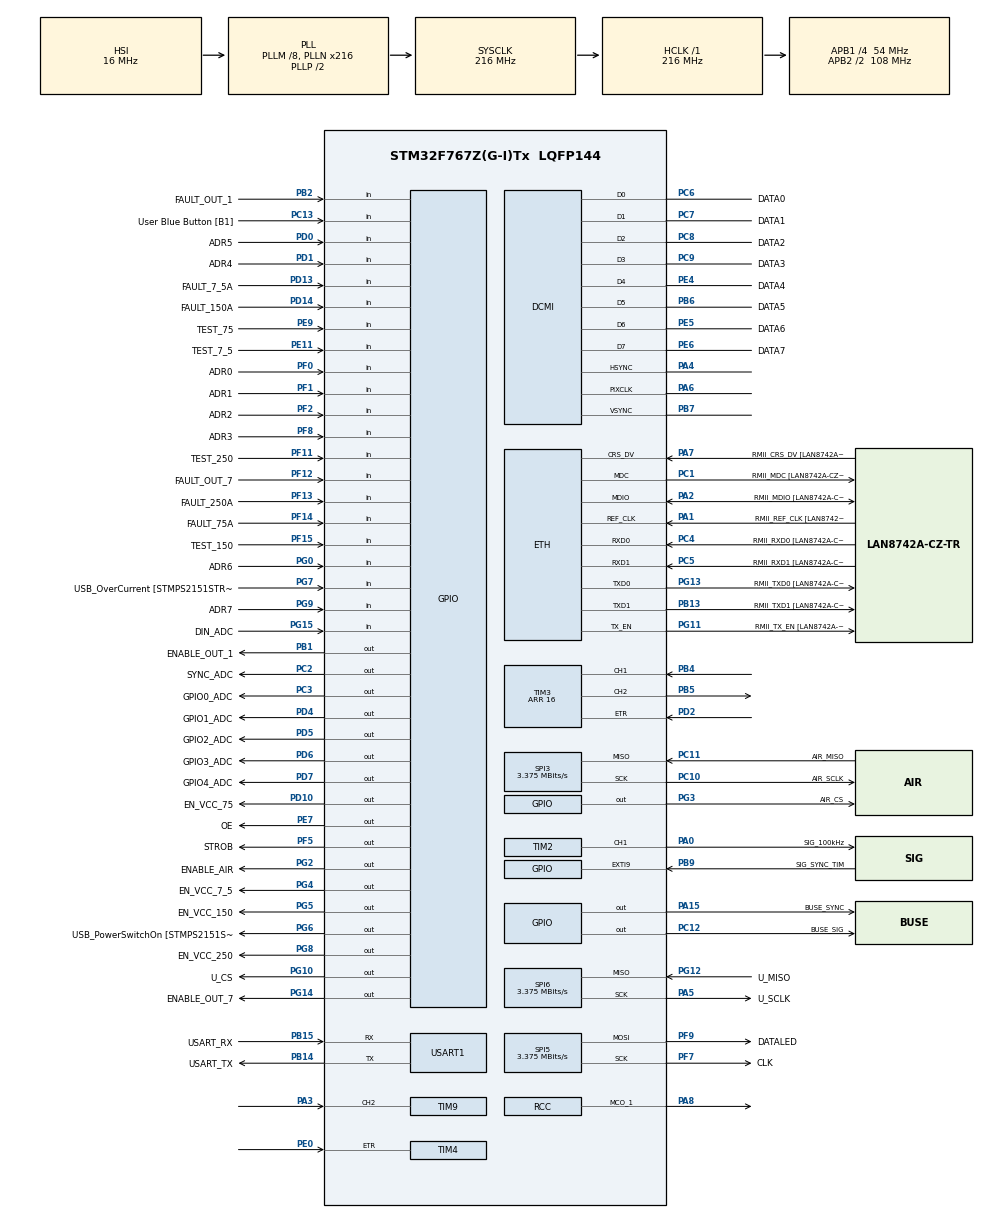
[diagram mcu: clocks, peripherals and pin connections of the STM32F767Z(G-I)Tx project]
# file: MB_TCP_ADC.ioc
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CORTEX_M7.ART_ACCLERATOR_ENABLE=1
CORTEX_M7.CPU_DCache=Disabled
CORTEX_M7.CPU_ICache=Enabled
CORTEX_M7.Enable-Cortex_Memory_Protection_Unit_Region0_Settings=__NULL
CORTEX_M7.MPU_Control=__NULL
CORTEX_M7.PREFETCH_ENABLE=1
Dma.DCMI.1.Direction=DMA_PERIPH_TO_MEMORY
Dma.DCMI.1.FIFOMode=DMA_FIFOMODE_DISABLE
Dma.DCMI.1.Instance=DMA2_Stream1
Dma.DCMI.1.MemDataAlignment=DMA_MDATAALIGN_WORD
Dma.DCMI.1.MemInc=DMA_MINC_ENABLE
Dma.DCMI.1.Mode=DMA_CIRCULAR
Dma.DCMI.1.PeriphDataAlignment=DMA_PDATAALIGN_WORD
Dma.DCMI.1.PeriphInc=DMA_PINC_DISABLE
Dma.DCMI.1.Priority=DMA_PRIORITY_LOW
Dma.Request0=SPI3_RX
Dma.Request1=DCMI
Dma.Request2=SPI6_RX
Dma.Request3=SPI5_TX
Dma.Request4=USART1_RX
Dma.Request5=USART1_TX
Dma.SPI3_RX.0.Direction=DMA_PERIPH_TO_MEMORY
Dma.SPI3_RX.0.FIFOMode=DMA_FIFOMODE_DISABLE
Dma.SPI3_RX.0.Instance=DMA1_Stream0
Dma.SPI3_RX.0.MemDataAlignment=DMA_MDATAALIGN_BYTE
Dma.SPI3_RX.0.MemInc=DMA_MINC_ENABLE
Dma.SPI3_RX.0.Mode=DMA_NORMAL
Dma.SPI3_RX.0.PeriphDataAlignment=DMA_PDATAALIGN_BYTE
Dma.SPI3_RX.0.PeriphInc=DMA_PINC_DISABLE
Dma.SPI3_RX.0.Priority=DMA_PRIORITY_LOW
Dma.SPI5_TX.3.Direction=DMA_MEMORY_TO_PERIPH
Dma.SPI5_TX.3.FIFOMode=DMA_FIFOMODE_DISABLE
Dma.SPI5_TX.3.Instance=DMA2_Stream4
Dma.SPI5_TX.3.MemDataAlignment=DMA_MDATAALIGN_BYTE
Dma.SPI5_TX.3.MemInc=DMA_MINC_ENABLE
Dma.SPI5_TX.3.Mode=DMA_NORMAL
Dma.SPI5_TX.3.PeriphDataAlignment=DMA_PDATAALIGN_BYTE
Dma.SPI5_TX.3.PeriphInc=DMA_PINC_DISABLE
Dma.SPI5_TX.3.Priority=DMA_PRIORITY_VERY_HIGH
Dma.SPI6_RX.2.Direction=DMA_PERIPH_TO_MEMORY
Dma.SPI6_RX.2.FIFOMode=DMA_FIFOMODE_DISABLE
Dma.SPI6_RX.2.Instance=DMA2_Stream6
Dma.SPI6_RX.2.MemDataAlignment=DMA_MDATAALIGN_BYTE
Dma.SPI6_RX.2.MemInc=DMA_MINC_ENABLE
Dma.SPI6_RX.2.Mode=DMA_NORMAL
Dma.SPI6_RX.2.PeriphDataAlignment=DMA_PDATAALIGN_BYTE
Dma.SPI6_RX.2.PeriphInc=DMA_PINC_DISABLE
Dma.SPI6_RX.2.Priority=DMA_PRIORITY_LOW
Dma.USART1_RX.4.Direction=DMA_PERIPH_TO_MEMORY
Dma.USART1_RX.4.FIFOMode=DMA_FIFOMODE_DISABLE
Dma.USART1_RX.4.Instance=DMA2_Stream2
Dma.USART1_RX.4.MemDataAlignment=DMA_MDATAALIGN_BYTE
Dma.USART1_RX.4.MemInc=DMA_MINC_ENABLE
Dma.USART1_RX.4.Mode=DMA_NORMAL
Dma.USART1_RX.4.PeriphDataAlignment=DMA_PDATAALIGN_BYTE
Dma.USART1_RX.4.PeriphInc=DMA_PINC_DISABLE
Dma.USART1_RX.4.Priority=DMA_PRIORITY_MEDIUM
Dma.USART1_TX.5.Direction=DMA_MEMORY_TO_PERIPH
Dma.USART1_TX.5.FIFOMode=DMA_FIFOMODE_DISABLE
Dma.USART1_TX.5.Instance=DMA2_Stream7
Dma.USART1_TX.5.MemDataAlignment=DMA_MDATAALIGN_BYTE
Dma.USART1_TX.5.MemInc=DMA_MINC_ENABLE
Dma.USART1_TX.5.Mode=DMA_NORMAL
Dma.USART1_TX.5.PeriphDataAlignment=DMA_PDATAALIGN_BYTE
Dma.USART1_TX.5.PeriphInc=DMA_PINC_DISABLE
Dma.USART1_TX.5.Priority=DMA_PRIORITY_MEDIUM
ETH.AutoNegotiation=ETH_AUTONEGOTIATION_ENABLE
ETH.MACAddr=00\:80\:E2\:20\:00\:00
ETH.MediaInterface=ETH_MEDIA_INTERFACE_RMII
ETH.PhyAddress=0
FREERTOS.INCLUDE_vTaskDelayUntil=1
FREERTOS.Tasks01=defaultTask,0,128,StartDefaultTask,Default,NULL,Dynamic,NULL,NULL
FREERTOS.configTOTAL_HEAP_SIZE=65536
LWIP.CHECKSUM_BY_HARDWARE=1
LWIP.GATEWAY_ADDRESS=192.168.109.008
LWIP.IP_ADDRESS=192.168.109.150
LWIP.LWIP_DHCP=0
LWIP.MEMP_NUM_RAW_PCB=8
LWIP.MEMP_NUM_UDP_PCB=1
LWIP.NETMASK_ADDRESS=255.255.255.000
LWIP.Version=v2.0.0_Cube
Mcu.Family=STM32F7
Mcu.Name=STM32F767Z(G-I)Tx
Mcu.Package=LQFP144
NVIC.DMA1_Stream0_IRQn=true\:5\:0\:false\:false\:true\:true\:true
NVIC.DMA2_Stream1_IRQn=true\:5\:0\:false\:false\:true\:true\:true
NVIC.DMA2_Stream2_IRQn=true\:5\:0\:false\:false\:true\:true\:true
NVIC.DMA2_Stream4_IRQn=true\:5\:0\:false\:false\:true\:true\:true
NVIC.DMA2_Stream6_IRQn=true\:5\:0\:false\:false\:true\:true\:true
NVIC.DMA2_Stream7_IRQn=true\:5\:0\:false\:false\:true\:true\:true
NVIC.ETH_IRQn=true\:5\:0\:true\:false\:true\:true\:true
NVIC.EXTI9_5_IRQn=true\:5\:0\:false\:false\:true\:true\:true
NVIC.PriorityGroup=NVIC_PRIORITYGROUP_4
NVIC.TIM1_BRK_TIM9_IRQn=true\:5\:0\:false\:false\:true\:true\:true
NVIC.TIM6_DAC_IRQn=true\:5\:0\:false\:false\:true\:true\:true
NVIC.USART1_IRQn=true\:5\:0\:false\:false\:true\:true\:true
PA0/WKUP.GPIO_Label=SIG_100kHz
PA0/WKUP.Signal=S_TIM2_CH1_ETR
PA1.GPIO_Label=RMII_REF_CLK [LAN8742A-CZ-TR_REFCLK0]
PA1.Mode=RMII
PA1.Signal=ETH_REF_CLK
PA13.GPIO_Label=TMS
PA13.Mode=Trace_Asynchronous_SW
PA13.Signal=SYS_JTMS-SWDIO
PA14.GPIO_Label=TCK
PA14.Mode=Trace_Asynchronous_SW
PA14.Signal=SYS_JTCK-SWCLK
PA15.GPIO_Label=BUSE_SYNC
PA15.PinState=GPIO_PIN_SET
PA15.Signal=GPIO_Output
PA2.GPIO_Label=RMII_MDIO [LAN8742A-CZ-TR_MDIO]
PA2.Mode=RMII
PA2.Signal=ETH_MDIO
PA3.Signal=S_TIM9_CH2
PA4.Mode=Slave_8_bits_External_Synchro
PA4.Signal=DCMI_HSYNC
PA5.GPIO_Label=U_SCLK
PA5.Mode=RX_Only_Simplex_Unidirect_Master
PA5.Signal=SPI6_SCK
PA6.Mode=Slave_8_bits_External_Synchro
PA6.Signal=DCMI_PIXCLK
PA7.GPIO_Label=RMII_CRS_DV [LAN8742A-CZ-TR_CRS_DV]
PA7.Mode=RMII
PA7.Signal=ETH_CRS_DV
PA8.Mode=Clock-out-1
PA8.Signal=RCC_MCO_1
PB1.GPIO_Label=ENABLE_OUT_1
PB1.PinState=GPIO_PIN_RESET
PB1.Signal=GPIO_Output
PB13.GPIO_Label=RMII_TXD1 [LAN8742A-CZ-TR_TXD1]
PB13.Mode=RMII
PB13.Signal=ETH_TXD1
PB14.GPIO_Label=USART_TX
PB14.Mode=Asynchronous
PB14.Signal=USART1_TX
PB15.GPIO_Label=USART_RX
PB15.Mode=Asynchronous
PB15.Signal=USART1_RX
PB2.GPIO_Label=FAULT_OUT_1
PB2.Signal=GPIO_Input
PB3.Mode=Trace_Asynchronous_SW
PB3.Signal=SYS_JTDO-SWO
PB4.Signal=S_TIM3_CH1
PB5.Signal=S_TIM3_CH2
PB6.GPIO_Label=DATA5
PB6.Mode=Slave_8_bits_External_Synchro
PB6.Signal=DCMI_D5
PB7.Mode=Slave_8_bits_External_Synchro
PB7.Signal=DCMI_VSYNC
PB9.GPIO_Label=SIG_SYNC_TIM
PB9.Signal=GPXTI9
PC1.GPIO_Label=RMII_MDC [LAN8742A-CZ-TR_MDC]
PC1.Mode=RMII
PC1.Signal=ETH_MDC
PC10.GPIO_Label=AIR_SCLK
PC10.Mode=RX_Only_Simplex_Unidirect_Master
PC10.Signal=SPI3_SCK
PC11.GPIO_Label=AIR_MISO
PC11.Mode=RX_Only_Simplex_Unidirect_Master
PC11.Signal=SPI3_MISO
PC12.GPIO_Label=BUSE_SIG
PC12.Signal=GPIO_Output
PC13.GPIO_Label=User Blue Button [B1]
PC13.Signal=GPIO_Input
PC14/OSC32_IN.Signal=RCC_OSC32_IN
PC15/OSC32_OUT.Signal=RCC_OSC32_OUT
PC2.GPIO_Label=SYNC_ADC
PC2.Signal=GPIO_Output
PC3.GPIO_Label=GPIO0_ADC
PC3.Signal=GPIO_Output
PC4.GPIO_Label=RMII_RXD0 [LAN8742A-CZ-TR_RXD0]
PC4.Mode=RMII
PC4.Signal=ETH_RXD0
PC5.GPIO_Label=RMII_RXD1 [LAN8742A-CZ-TR_RXD1]
PC5.Mode=RMII
PC5.Signal=ETH_RXD1
PC6.GPIO_Label=DATA0
PC6.Mode=Slave_8_bits_External_Synchro
PC6.Signal=DCMI_D0
PC7.GPIO_Label=DATA1
PC7.Mode=Slave_8_bits_External_Synchro
PC7.Signal=DCMI_D1
PC8.GPIO_Label=DATA2
PC8.Mode=Slave_8_bits_External_Synchro
PC8.Signal=DCMI_D2
PC9.GPIO_Label=DATA3
PC9.Mode=Slave_8_bits_External_Synchro
PC9.Signal=DCMI_D3
PD0.GPIO_Label=ADR5
PD0.GPIO_PuPd=GPIO_PULLDOWN
PD0.Signal=GPIO_Input
PD1.GPIO_Label=ADR4
PD1.GPIO_PuPd=GPIO_PULLDOWN
PD1.Signal=GPIO_Input
PD10.GPIO_Label=EN_VCC_75
PD10.Signal=GPIO_Output
PD13.GPIO_Label=FAULT_7_5A
PD13.Signal=GPIO_Input
PD14.GPIO_Label=FAULT_150A
PD14.Signal=GPIO_Input
PD2.Signal=S_TIM3_ETR
PD4.GPIO_Label=GPIO1_ADC
PD4.Signal=GPIO_Output
PD5.GPIO_Label=GPIO2_ADC
PD5.Signal=GPIO_Output
PD6.GPIO_Label=GPIO3_ADC
PD6.Signal=GPIO_Output
PD7.GPIO_Label=GPIO4_ADC
PD7.Signal=GPIO_Output
PD8.GPIO_Label=STLK_RX [STM32F103CBT6_PA3]
PD8.Signal=USART3_TX
PD9.GPIO_Label=STLK_TX [STM32F103CBT6_PA2]
PD9.Signal=USART3_RX
PE0.Signal=S_TIM4_ETR
PE11.GPIO_Label=TEST_7_5
PE11.Signal=GPIO_Input
PE4.GPIO_Label=DATA4
PE4.Mode=Slave_8_bits_External_Synchro
PE4.Signal=DCMI_D4
PE5.GPIO_Label=DATA6
PE5.Mode=Slave_8_bits_External_Synchro
PE5.Signal=DCMI_D6
PE6.GPIO_Label=DATA7
PE6.Mode=Slave_8_bits_External_Synchro
PE6.Signal=DCMI_D7
PE7.GPIO_Label=OE
PE7.Signal=GPIO_Output
PE9.GPIO_Label=TEST_75
PE9.Signal=GPIO_Input
PF0.GPIO_Label=ADR0
PF0.GPIO_PuPd=GPIO_PULLDOWN
PF0.Signal=GPIO_Input
PF1.GPIO_Label=ADR1
PF1.GPIO_PuPd=GPIO_PULLDOWN
PF1.Signal=GPIO_Input
PF11.GPIO_Label=TEST_250
PF11.Signal=GPIO_Input
PF12.GPIO_Label=FAULT_OUT_7
PF12.Signal=GPIO_Input
PF13.GPIO_Label=FAULT_250A
PF13.Signal=GPIO_Input
PF14.GPIO_Label=FAULT_75A
PF14.Signal=GPIO_Input
PF15.GPIO_Label=TEST_150
PF15.Signal=GPIO_Input
PF2.GPIO_Label=ADR2
PF2.GPIO_PuPd=GPIO_PULLDOWN
PF2.Signal=GPIO_Input
PF5.GPIO_Label=STROB
PF5.Signal=GPIO_Output
PF7.GPIO_Label=CLK
PF7.Mode=TX_Only_Simplex_Unidirect_Master
PF7.Signal=SPI5_SCK
PF8.GPIO_Label=ADR3
PF8.Signal=GPIO_Input
PF9.GPIO_Label=DATALED
PF9.Mode=TX_Only_Simplex_Unidirect_Master
PF9.Signal=SPI5_MOSI
PG0.GPIO_Label=ADR6
PG0.GPIO_PuPd=GPIO_PULLUP
PG0.Signal=GPIO_Input
PG10.GPIO_Label=U_CS
PG10.Signal=GPIO_Output
PG11.GPIO_Label=RMII_TX_EN [LAN8742A-CZ-TR_TXEN]
PG11.Mode=RMII
PG11.Signal=ETH_TX_EN
PG12.GPIO_Label=U_MISO
PG12.Mode=RX_Only_Simplex_Unidirect_Master
PG12.Signal=SPI6_MISO
PG13.GPIO_Label=RMII_TXD0 [LAN8742A-CZ-TR_TXD0]
PG13.Mode=RMII
PG13.Signal=ETH_TXD0
PG14.GPIO_Label=ENABLE_OUT_7
PG14.PinState=GPIO_PIN_SET
PG14.Signal=GPIO_Output
PG15.GPIO_Label=DIN_ADC
PG15.Signal=GPIO_Input
PG2.GPIO_Label=ENABLE_AIR
PG2.Signal=GPIO_Output
PG3.GPIO_Label=AIR_CS
PG3.Signal=GPIO_Output
PG4.GPIO_Label=EN_VCC_7_5
PG4.Signal=GPIO_Output
PG5.GPIO_Label=EN_VCC_150
PG5.Signal=GPIO_Output
PG6.GPIO_Label=USB_PowerSwitchOn [STMPS2151STR_EN]
PG6.Signal=GPIO_Output
PG7.GPIO_Label=USB_OverCurrent [STMPS2151STR_FAULT]
PG7.Signal=GPIO_Input
PG8.GPIO_Label=EN_VCC_250
PG8.Signal=GPIO_Output
PG9.GPIO_Label=ADR7
PG9.GPIO_PuPd=GPIO_PULLUP
PG9.Signal=GPIO_Input
PH0/OSC_IN.GPIO_Label=MCO [STM32F103CBT6_PA8]
PH0/OSC_IN.Mode=HSE-External-Oscillator
PH0/OSC_IN.Signal=RCC_OSC_IN
PH1/OSC_OUT.Mode=HSE-External-Oscillator
PH1/OSC_OUT.Signal=RCC_OSC_OUT
ProjectManager.HeapSize=0x2000
ProjectManager.StackSize=0x4000
ProjectManager.TargetToolchain=MDK-ARM V5
RCC.48MHZClocksFreq_Value=24000000
RCC.AHBFreq_Value=216000000
RCC.APB1CLKDivider=RCC_HCLK_DIV4
RCC.APB1Freq_Value=54000000
RCC.APB1TimFreq_Value=108000000
RCC.APB2CLKDivider=RCC_HCLK_DIV2
RCC.APB2Freq_Value=108000000
RCC.APB2TimFreq_Value=216000000
RCC.CortexFreq_Value=216000000
RCC.HCLKFreq_Value=216000000
RCC.HSE_VALUE=8000000
RCC.HSI_VALUE=16000000
RCC.LSE_VALUE=32768
RCC.PLLM=8
RCC.PLLMUL=RCC_PLL_MUL9
RCC.PLLN=216
RCC.PRESCALERUSB=RCC_USBCLKSOURCE_PLL_DIV1_5
RCC.RCC_MCODiv1=RCC_MCODIV_2
RCC.SYSCLKFreq_VALUE=216000000
RCC.SYSCLKSource=RCC_SYSCLKSOURCE_PLLCLK
RCC.SYSCLKSourceVirtual=RCC_SYSCLKSOURCE_PLLCLK
RCC.USBFreq_Value=216000000
RCC.VCOOutputFreq_Value=432000000
SH.S_TIM2_CH1_ETR.0=TIM2_CH1,PWM Generation1 CH1
SH.S_TIM3_CH1.0=TIM3_CH1,TriggerSource_TI1FP1
SH.S_TIM3_CH2.0=TIM3_CH2,PWM Generation2 CH2
SH.S_TIM3_ETR.0=TIM3_ETR,ClockSourceETR_Mode2
SH.S_TIM4_ETR.0=TIM4_ETR,ClockSourceETR_Mode2
SH.S_TIM9_CH2.0=TIM9_CH2,TriggerSource_TI2FP2
SPI3.BaudRatePrescaler=SPI_BAUDRATEPRESCALER_16
SPI3.CLKPolarity=SPI_POLARITY_HIGH
SPI3.CalculateBaudRate=3.375 MBits/s
SPI3.DataSize=SPI_DATASIZE_8BIT
SPI3.Direction=SPI_DIRECTION_2LINES_RXONLY
SPI3.Mode=SPI_MODE_MASTER
SPI3.NSSPMode=SPI_NSS_PULSE_DISABLE
SPI3.VirtualType=VM_MASTER
SPI5.BaudRatePrescaler=SPI_BAUDRATEPRESCALER_32
SPI5.CalculateBaudRate=3.375 MBits/s
SPI5.DataSize=SPI_DATASIZE_8BIT
SPI5.Direction=SPI_DIRECTION_2LINES
SPI5.Mode=SPI_MODE_MASTER
SPI5.NSSPMode=SPI_NSS_PULSE_DISABLE
SPI5.VirtualType=VM_MASTER
SPI6.BaudRatePrescaler=SPI_BAUDRATEPRESCALER_32
SPI6.CLKPolarity=SPI_POLARITY_HIGH
SPI6.CalculateBaudRate=3.375 MBits/s
SPI6.DataSize=SPI_DATASIZE_8BIT
SPI6.Direction=SPI_DIRECTION_2LINES_RXONLY
SPI6.Mode=SPI_MODE_MASTER
SPI6.NSSPMode=SPI_NSS_PULSE_DISABLE
SPI6.VirtualType=VM_MASTER
TIM2.Channel-PWM\ Generation1\ CH1=TIM_CHANNEL_1
TIM2.Period=1080
TIM2.Pulse-PWM\ Generation1\ CH1=540
TIM2.TIM_MasterOutputTrigger=TIM_TRGO_UPDATE
TIM2.TIM_MasterSlaveMode=TIM_MASTERSLAVEMODE_ENABLE
TIM3.Channel-PWM\ Generation2\ CH2=TIM_CHANNEL_2
TIM3.OCMode_PWM-PWM\ Generation2\ CH2=TIM_OCMODE_PWM2
TIM3.Period=16
TIM3.Pulse-PWM\ Generation2\ CH2=1
TIM4.Period=0xFFFF
TIM4.Prescaler=0
TIM4.TIM_MasterOutputTrigger=TIM_TRGO_UPDATE
TIM4.TIM_MasterSlaveMode=TIM_MASTERSLAVEMODE_ENABLE
TIM5.Period=0xFFFFFFFF
TIM6.Period=50-1
TIM6.Prescaler=108
TIM9.Period=4-1
USART1.VirtualMode-Asynchronous=VM_ASYNC
VP_FREERTOS_VS_ENABLE.Mode=Enabled
VP_LWIP_VS_Enabled.Mode=Enabled
VP_TIM2_VS_ClockSourceINT.Mode=Internal
VP_TIM3_VS_ControllerModeTrigger.Mode=Trigger Mode
VP_TIM3_VS_OPM.Mode=OPM_bit
VP_TIM5_VS_ClockSourceITR.Mode=TriggerSource_ITR2
VP_TIM5_VS_ControllerModeClock.Mode=Clock Mode
VP_TIM6_VS_ClockSourceINT.Mode=Enable_Timer
VP_TIM9_VS_ControllerModeClock.Mode=Clock Mode
board=MB_TCP_ADC

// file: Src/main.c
/**
  ******************************************************************************
  * File Name          : main.c
  * Description        : Main program body
  ******************************************************************************
  * This notice applies to any and all portions of this file
  * that are not between comment pairs USER CODE BEGIN and
  * USER CODE END. Other portions of this file, whether
  * inserted by the user or by software development tools
  * are owned by their respective copyright owners.
  *
  * Copyright (c) 2017 STMicroelectronics International N.V.
  * All rights reserved.
  *
  * Redistribution and use in source and binary forms, with or without
  * modification, are permitted, provided that the following conditions are met:
  *
  * 1. Redistribution of source code must retain the above copyright notice,
  *    this list of conditions and the following disclaimer.
  * 2. Redistributions in binary form must reproduce the above copyright notice,
  *    this list of conditions and the following disclaimer in the documentation
  *    and/or other materials provided with the distribution.
  * 3. Neither the name of STMicroelectronics nor the names of other
  *    contributors to this software may be used to endorse or promote products
  *    derived from this software without specific written permission.
  * 4. This software, including modifications and/or derivative works of this
  *    software, must execute solely and exclusively on microcontroller or
  *    microprocessor devices manufactured by or for STMicroelectronics.
  * 5. Redistribution and use of this software other than as permitted under
  *    this license is void and will automatically terminate your rights under
  *    this license.
  *
  * THIS SOFTWARE IS PROVIDED BY STMICROELECTRONICS AND CONTRIBUTORS "AS IS"
  * AND ANY EXPRESS, IMPLIED OR STATUTORY WARRANTIES, INCLUDING, BUT NOT
  * LIMITED TO, THE IMPLIED WARRANTIES OF MERCHANTABILITY, FITNESS FOR A
  * PARTICULAR PURPOSE AND NON-INFRINGEMENT OF THIRD PARTY INTELLECTUAL PROPERTY
  * RIGHTS ARE DISCLAIMED TO THE FULLEST EXTENT PERMITTED BY LAW. IN NO EVENT
  * SHALL STMICROELECTRONICS OR CONTRIBUTORS BE LIABLE FOR ANY DIRECT, INDIRECT,
  * INCIDENTAL, SPECIAL, EXEMPLARY, OR CONSEQUENTIAL DAMAGES (INCLUDING, BUT NOT
  * LIMITED TO, PROCUREMENT OF SUBSTITUTE GOODS OR SERVICES; LOSS OF USE, DATA,
  * OR PROFITS; OR BUSINESS INTERRUPTION) HOWEVER CAUSED AND ON ANY THEORY OF
  * LIABILITY, WHETHER IN CONTRACT, STRICT LIABILITY, OR TORT (INCLUDING
  * NEGLIGENCE OR OTHERWISE) ARISING IN ANY WAY OUT OF THE USE OF THIS SOFTWARE,
  * EVEN IF ADVISED OF THE POSSIBILITY OF SUCH DAMAGE.
  *
  ******************************************************************************
  */
#include "main.h"
#include "stm32f7xx_hal.h"
#include "cmsis_os.h"
#include "lwip.h"

/* USER CODE BEGIN Includes */
#include "mbinit.h"
#include "udp_send.h"
#include "adc_dcmi.h"
#include "cfg_info.h"
#include "discret_out.h"
#include "jumpers.h"
#include "mbmasterpyro.h"
/* USER CODE END Includes */

DCMI_HandleTypeDef hdcmi;
DMA_HandleTypeDef hdma_dcmi;

SPI_HandleTypeDef hspi3;
SPI_HandleTypeDef hspi5;
SPI_HandleTypeDef hspi6;
DMA_HandleTypeDef hdma_spi3_rx;
DMA_HandleTypeDef hdma_spi5_tx;
DMA_HandleTypeDef hdma_spi6_rx;

TIM_HandleTypeDef htim2;
TIM_HandleTypeDef htim3;
TIM_HandleTypeDef htim4;
TIM_HandleTypeDef htim5;
TIM_HandleTypeDef htim6;
TIM_HandleTypeDef htim9;

UART_HandleTypeDef huart1;
DMA_HandleTypeDef hdma_usart1_rx;
DMA_HandleTypeDef hdma_usart1_tx;

osThreadId defaultTaskHandle;

/* USER CODE BEGIN PV */
/* Private variables ---------------------------------------------------------*/

/* USER CODE END PV */

void SystemClock_Config(void);
static void MX_GPIO_Init(void);
static void MX_DMA_Init(void);
static void MX_DCMI_Init(void);
static void MX_TIM2_Init(void);
static void MX_TIM3_Init(void);
static void MX_TIM4_Init(void);
static void MX_TIM5_Init(void);
static void MX_USART1_UART_Init(void);
static void MX_SPI3_Init(void);
static void MX_SPI6_Init(void);
static void MX_TIM9_Init(void);
static void MX_SPI5_Init(void);
static void MX_TIM6_Init(void);
void StartDefaultTask(void const * argument);

void HAL_TIM_MspPostInit(TIM_HandleTypeDef *htim);

/* USER CODE BEGIN PFP */
/* Private function prototypes -----------------------------------------------*/

/* USER CODE END PFP */

/* USER CODE BEGIN 0 */
#include <stdio.h>

int fputc(int c, FILE *stream)
{
   return(ITM_SendChar(c));
}
/* USER CODE END 0 */

int main(void)
{

  /* Enable I-Cache-------------------------------------------------------------*/
  SCB_EnableICache();

  /* MCU Configuration----------------------------------------------------------*/

  /* Reset of all peripherals, Initializes the Flash interface and the Systick. */
  HAL_Init();

  /* Configure the system clock */
  SystemClock_Config();

  /* Initialize all configured peripherals */
  MX_GPIO_Init();
  MX_DMA_Init();
  MX_DCMI_Init();
  MX_TIM2_Init();
  MX_TIM3_Init();
  MX_TIM4_Init();
  MX_TIM5_Init();
  MX_USART1_UART_Init();
  MX_SPI3_Init();
  MX_SPI6_Init();
  MX_TIM9_Init();
  MX_SPI5_Init();
  MX_TIM6_Init();

  /* USER CODE BEGIN 2 */
	ConfigInfoRead();
	Jumpers_ReadSettings();
	DiscretOutputs_Init();
	DCMI_ADC_Init();
	ADC_DataConverter_Init();

  /* USER CODE END 2 */

  /* Create the thread(s) */
  /* definition and creation of defaultTask */
  osThreadDef(defaultTask, StartDefaultTask, osPriorityNormal, 0, 128);
  defaultTaskHandle = osThreadCreate(osThread(defaultTask), NULL);

  /* USER CODE BEGIN RTOS_QUEUES */
  /* add queues, ... */
		printf("Init");
		//HAL_TIM_PWM_Start(&htim2,TIM_CHANNEL_1);

  /* USER CODE END RTOS_QUEUES */

  /* Start scheduler */
  osKernelStart();

  /* We should never get here as control is now taken by the scheduler */

  /* Infinite loop */
  while (1)
  {

  }

}

/** System Clock Configuration
*/
void SystemClock_Config(void)
{

  RCC_OscInitTypeDef RCC_OscInitStruct;
  RCC_ClkInitTypeDef RCC_ClkInitStruct;
  RCC_PeriphCLKInitTypeDef PeriphClkInitStruct;

    /**Configure the main internal regulator output voltage
    */
  __HAL_RCC_PWR_CLK_ENABLE();

  __HAL_PWR_VOLTAGESCALING_CONFIG(PWR_REGULATOR_VOLTAGE_SCALE1);

    /**Initializes the CPU, AHB and APB busses clocks
    */
  RCC_OscInitStruct.OscillatorType = RCC_OSCILLATORTYPE_HSI;
  RCC_OscInitStruct.HSIState = RCC_HSI_ON;
  RCC_OscInitStruct.HSICalibrationValue = 16;
  RCC_OscInitStruct.PLL.PLLState = RCC_PLL_ON;
  RCC_OscInitStruct.PLL.PLLSource = RCC_PLLSOURCE_HSI;
  RCC_OscInitStruct.PLL.PLLM = 8;
  RCC_OscInitStruct.PLL.PLLN = 216;
  RCC_OscInitStruct.PLL.PLLP = RCC_PLLP_DIV2;
  RCC_OscInitStruct.PLL.PLLQ = 2;
  if (HAL_RCC_OscConfig(&RCC_OscInitStruct) != HAL_OK)
  {
    _Error_Handler(__FILE__, __LINE__);
  }

    /**Activate the Over-Drive mode
    */
  if (HAL_PWREx_EnableOverDrive() != HAL_OK)
  {
    _Error_Handler(__FILE__, __LINE__);
  }

    /**Initializes the CPU, AHB and APB busses clocks
    */
  RCC_ClkInitStruct.ClockType = RCC_CLOCKTYPE_HCLK|RCC_CLOCKTYPE_SYSCLK
                              |RCC_CLOCKTYPE_PCLK1|RCC_CLOCKTYPE_PCLK2;
  RCC_ClkInitStruct.SYSCLKSource = RCC_SYSCLKSOURCE_PLLCLK;
  RCC_ClkInitStruct.AHBCLKDivider = RCC_SYSCLK_DIV1;
  RCC_ClkInitStruct.APB1CLKDivider = RCC_HCLK_DIV4;
  RCC_ClkInitStruct.APB2CLKDivider = RCC_HCLK_DIV2;

  if (HAL_RCC_ClockConfig(&RCC_ClkInitStruct, FLASH_LATENCY_7) != HAL_OK)
  {
    _Error_Handler(__FILE__, __LINE__);
  }

  PeriphClkInitStruct.PeriphClockSelection = RCC_PERIPHCLK_USART1;
  PeriphClkInitStruct.Usart1ClockSelection = RCC_USART1CLKSOURCE_PCLK2;
  if (HAL_RCCEx_PeriphCLKConfig(&PeriphClkInitStruct) != HAL_OK)
  {
    _Error_Handler(__FILE__, __LINE__);
  }

  HAL_RCC_MCOConfig(RCC_MCO1, RCC_MCO1SOURCE_HSI, RCC_MCODIV_2);

    /**Configure the Systick interrupt time
    */
  HAL_SYSTICK_Config(HAL_RCC_GetHCLKFreq()/1000);

    /**Configure the Systick
    */
  HAL_SYSTICK_CLKSourceConfig(SYSTICK_CLKSOURCE_HCLK);

  /* SysTick_IRQn interrupt configuration */
  HAL_NVIC_SetPriority(SysTick_IRQn, 15, 0);
}

/* DCMI init function */
static void MX_DCMI_Init(void)
{

  hdcmi.Instance = DCMI;
  hdcmi.Init.SynchroMode = DCMI_SYNCHRO_HARDWARE;
  hdcmi.Init.PCKPolarity = DCMI_PCKPOLARITY_FALLING;
  hdcmi.Init.VSPolarity = DCMI_VSPOLARITY_LOW;
  hdcmi.Init.HSPolarity = DCMI_HSPOLARITY_LOW;
  hdcmi.Init.CaptureRate = DCMI_CR_ALL_FRAME;
  hdcmi.Init.ExtendedDataMode = DCMI_EXTEND_DATA_8B;
  hdcmi.Init.JPEGMode = DCMI_JPEG_DISABLE;
  hdcmi.Init.ByteSelectMode = DCMI_BSM_ALL;
  hdcmi.Init.ByteSelectStart = DCMI_OEBS_ODD;
  hdcmi.Init.LineSelectMode = DCMI_LSM_ALL;
  hdcmi.Init.LineSelectStart = DCMI_OELS_ODD;
  if (HAL_DCMI_Init(&hdcmi) != HAL_OK)
  {
    _Error_Handler(__FILE__, __LINE__);
  }

}

/* SPI3 init function */
static void MX_SPI3_Init(void)
{

  /* SPI3 parameter configuration*/
  hspi3.Instance = SPI3;
  hspi3.Init.Mode = SPI_MODE_MASTER;
  hspi3.Init.Direction = SPI_DIRECTION_2LINES_RXONLY;
  hspi3.Init.DataSize = SPI_DATASIZE_8BIT;
  hspi3.Init.CLKPolarity = SPI_POLARITY_HIGH;
  hspi3.Init.CLKPhase = SPI_PHASE_1EDGE;
  hspi3.Init.NSS = SPI_NSS_SOFT;
  hspi3.Init.BaudRatePrescaler = SPI_BAUDRATEPRESCALER_16;
  hspi3.Init.FirstBit = SPI_FIRSTBIT_MSB;
  hspi3.Init.TIMode = SPI_TIMODE_DISABLE;
  hspi3.Init.CRCCalculation = SPI_CRCCALCULATION_DISABLE;
  hspi3.Init.CRCPolynomial = 7;
  hspi3.Init.CRCLength = SPI_CRC_LENGTH_DATASIZE;
  hspi3.Init.NSSPMode = SPI_NSS_PULSE_DISABLE;
  if (HAL_SPI_Init(&hspi3) != HAL_OK)
  {
    _Error_Handler(__FILE__, __LINE__);
  }

}

/* SPI5 init function */
static void MX_SPI5_Init(void)
{

  /* SPI5 parameter configuration*/
  hspi5.Instance = SPI5;
  hspi5.Init.Mode = SPI_MODE_MASTER;
  hspi5.Init.Direction = SPI_DIRECTION_2LINES;
  hspi5.Init.DataSize = SPI_DATASIZE_8BIT;
  hspi5.Init.CLKPolarity = SPI_POLARITY_LOW;
  hspi5.Init.CLKPhase = SPI_PHASE_1EDGE;
  hspi5.Init.NSS = SPI_NSS_SOFT;
  hspi5.Init.BaudRatePrescaler = SPI_BAUDRATEPRESCALER_32;
  hspi5.Init.FirstBit = SPI_FIRSTBIT_MSB;
  hspi5.Init.TIMode = SPI_TIMODE_DISABLE;
  hspi5.Init.CRCCalculation = SPI_CRCCALCULATION_DISABLE;
  hspi5.Init.CRCPolynomial = 7;
  hspi5.Init.CRCLength = SPI_CRC_LENGTH_DATASIZE;
  hspi5.Init.NSSPMode = SPI_NSS_PULSE_DISABLE;
  if (HAL_SPI_Init(&hspi5) != HAL_OK)
  {
    _Error_Handler(__FILE__, __LINE__);
  }

}

/* SPI6 init function */
static void MX_SPI6_Init(void)
{

  /* SPI6 parameter configuration*/
  hspi6.Instance = SPI6;
  hspi6.Init.Mode = SPI_MODE_MASTER;
  hspi6.Init.Direction = SPI_DIRECTION_2LINES_RXONLY;
  hspi6.Init.DataSize = SPI_DATASIZE_8BIT;
  hspi6.Init.CLKPolarity = SPI_POLARITY_HIGH;
  hspi6.Init.CLKPhase = SPI_PHASE_1EDGE;
  hspi6.Init.NSS = SPI_NSS_SOFT;
  hspi6.Init.BaudRatePrescaler = SPI_BAUDRATEPRESCALER_32;
  hspi6.Init.FirstBit = SPI_FIRSTBIT_MSB;
  hspi6.Init.TIMode = SPI_TIMODE_DISABLE;
  hspi6.Init.CRCCalculation = SPI_CRCCALCULATION_DISABLE;
  hspi6.Init.CRCPolynomial = 7;
  hspi6.Init.CRCLength = SPI_CRC_LENGTH_DATASIZE;
  hspi6.Init.NSSPMode = SPI_NSS_PULSE_DISABLE;
  if (HAL_SPI_Init(&hspi6) != HAL_OK)
  {
    _Error_Handler(__FILE__, __LINE__);
  }

}

/* TIM2 init function */
static void MX_TIM2_Init(void)
{

  TIM_ClockConfigTypeDef sClockSourceConfig;
  TIM_MasterConfigTypeDef sMasterConfig;
  TIM_OC_InitTypeDef sConfigOC;

  htim2.Instance = TIM2;
  htim2.Init.Prescaler = 0;
  htim2.Init.CounterMode = TIM_COUNTERMODE_UP;
  htim2.Init.Period = 1080;
  htim2.Init.ClockDivision = TIM_CLOCKDIVISION_DIV1;
  htim2.Init.AutoReloadPreload = TIM_AUTORELOAD_PRELOAD_DISABLE;
  if (HAL_TIM_Base_Init(&htim2) != HAL_OK)
  {
    _Error_Handler(__FILE__, __LINE__);
  }

  sClockSourceConfig.ClockSource = TIM_CLOCKSOURCE_INTERNAL;
  if (HAL_TIM_ConfigClockSource(&htim2, &sClockSourceConfig) != HAL_OK)
  {
    _Error_Handler(__FILE__, __LINE__);
  }

  if (HAL_TIM_PWM_Init(&htim2) != HAL_OK)
  {
    _Error_Handler(__FILE__, __LINE__);
  }

  sMasterConfig.MasterOutputTrigger = TIM_TRGO_UPDATE;
  sMasterConfig.MasterSlaveMode = TIM_MASTERSLAVEMODE_ENABLE;
  if (HAL_TIMEx_MasterConfigSynchronization(&htim2, &sMasterConfig) != HAL_OK)
  {
    _Error_Handler(__FILE__, __LINE__);
  }

  sConfigOC.OCMode = TIM_OCMODE_PWM1;
  sConfigOC.Pulse = 540;
  sConfigOC.OCPolarity = TIM_OCPOLARITY_HIGH;
  sConfigOC.OCFastMode = TIM_OCFAST_DISABLE;
  if (HAL_TIM_PWM_ConfigChannel(&htim2, &sConfigOC, TIM_CHANNEL_1) != HAL_OK)
  {
    _Error_Handler(__FILE__, __LINE__);
  }

  HAL_TIM_MspPostInit(&htim2);

}

/* TIM3 init function */
static void MX_TIM3_Init(void)
{

  TIM_ClockConfigTypeDef sClockSourceConfig;
  TIM_SlaveConfigTypeDef sSlaveConfig;
  TIM_MasterConfigTypeDef sMasterConfig;
  TIM_OC_InitTypeDef sConfigOC;

  htim3.Instance = TIM3;
  htim3.Init.Prescaler = 0;
  htim3.Init.CounterMode = TIM_COUNTERMODE_UP;
  htim3.Init.Period = 16;
  htim3.Init.ClockDivision = TIM_CLOCKDIVISION_DIV1;
  htim3.Init.AutoReloadPreload = TIM_AUTORELOAD_PRELOAD_DISABLE;
  if (HAL_TIM_Base_Init(&htim3) != HAL_OK)
  {
    _Error_Handler(__FILE__, __LINE__);
  }

  sClockSourceConfig.ClockSource = TIM_CLOCKSOURCE_ETRMODE2;
  sClockSourceConfig.ClockPolarity = TIM_CLOCKPOLARITY_NONINVERTED;
  sClockSourceConfig.ClockPrescaler = TIM_CLOCKPRESCALER_DIV1;
  sClockSourceConfig.ClockFilter = 0;
  if (HAL_TIM_ConfigClockSource(&htim3, &sClockSourceConfig) != HAL_OK)
  {
    _Error_Handler(__FILE__, __LINE__);
  }

  if (HAL_TIM_PWM_Init(&htim3) != HAL_OK)
  {
    _Error_Handler(__FILE__, __LINE__);
  }

  if (HAL_TIM_OnePulse_Init(&htim3, TIM_OPMODE_SINGLE) != HAL_OK)
  {
    _Error_Handler(__FILE__, __LINE__);
  }

  sSlaveConfig.SlaveMode = TIM_SLAVEMODE_TRIGGER;
  sSlaveConfig.InputTrigger = TIM_TS_TI1FP1;
  sSlaveConfig.TriggerPolarity = TIM_TRIGGERPOLARITY_RISING;
  sSlaveConfig.TriggerFilter = 0;
  if (HAL_TIM_SlaveConfigSynchronization(&htim3, &sSlaveConfig) != HAL_OK)
  {
    _Error_Handler(__FILE__, __LINE__);
  }

  sMasterConfig.MasterOutputTrigger = TIM_TRGO_RESET;
  sMasterConfig.MasterSlaveMode = TIM_MASTERSLAVEMODE_DISABLE;
  if (HAL_TIMEx_MasterConfigSynchronization(&htim3, &sMasterConfig) != HAL_OK)
  {
    _Error_Handler(__FILE__, __LINE__);
  }

  sConfigOC.OCMode = TIM_OCMODE_PWM2;
  sConfigOC.Pulse = 1;
  sConfigOC.OCPolarity = TIM_OCPOLARITY_HIGH;
  sConfigOC.OCFastMode = TIM_OCFAST_DISABLE;
  if (HAL_TIM_PWM_ConfigChannel(&htim3, &sConfigOC, TIM_CHANNEL_2) != HAL_OK)
  {
    _Error_Handler(__FILE__, __LINE__);
  }

  HAL_TIM_MspPostInit(&htim3);

}

/* TIM4 init function */
static void MX_TIM4_Init(void)
{

  TIM_ClockConfigTypeDef sClockSourceConfig;
  TIM_MasterConfigTypeDef sMasterConfig;

  htim4.Instance = TIM4;
  htim4.Init.Prescaler = 0;
  htim4.Init.CounterMode = TIM_COUNTERMODE_UP;
  htim4.Init.Period = 0xFFFF;
  htim4.Init.ClockDivision = TIM_CLOCKDIVISION_DIV1;
  htim4.Init.AutoReloadPreload = TIM_AUTORELOAD_PRELOAD_DISABLE;
  if (HAL_TIM_Base_Init(&htim4) != HAL_OK)
  {
    _Error_Handler(__FILE__, __LINE__);
  }

  sClockSourceConfig.ClockSource = TIM_CLOCKSOURCE_ETRMODE2;
  sClockSourceConfig.ClockPolarity = TIM_CLOCKPOLARITY_NONINVERTED;
  sClockSourceConfig.ClockPrescaler = TIM_CLOCKPRESCALER_DIV1;
  sClockSourceConfig.ClockFilter = 0;
  if (HAL_TIM_ConfigClockSource(&htim4, &sClockSourceConfig) != HAL_OK)
  {
    _Error_Handler(__FILE__, __LINE__);
  }

  sMasterConfig.MasterOutputTrigger = TIM_TRGO_UPDATE;
  sMasterConfig.MasterSlaveMode = TIM_MASTERSLAVEMODE_ENABLE;
  if (HAL_TIMEx_MasterConfigSynchronization(&htim4, &sMasterConfig) != HAL_OK)
  {
    _Error_Handler(__FILE__, __LINE__);
  }

}

/* TIM5 init function */
static void MX_TIM5_Init(void)
{

  TIM_SlaveConfigTypeDef sSlaveConfig;
  TIM_MasterConfigTypeDef sMasterConfig;

  htim5.Instance = TIM5;
  htim5.Init.Prescaler = 0;
  htim5.Init.CounterMode = TIM_COUNTERMODE_UP;
  htim5.Init.Period = 0xFFFFFFFF;
  htim5.Init.ClockDivision = TIM_CLOCKDIVISION_DIV1;
  htim5.Init.AutoReloadPreload = TIM_AUTORELOAD_PRELOAD_DISABLE;
  if (HAL_TIM_Base_Init(&htim5) != HAL_OK)
  {
    _Error_Handler(__FILE__, __LINE__);
  }

  sSlaveConfig.SlaveMode = TIM_SLAVEMODE_EXTERNAL1;
  sSlaveConfig.InputTrigger = TIM_TS_ITR2;
  if (HAL_TIM_SlaveConfigSynchronization(&htim5, &sSlaveConfig) != HAL_OK)
  {
    _Error_Handler(__FILE__, __LINE__);
  }

  sMasterConfig.MasterOutputTrigger = TIM_TRGO_RESET;
  sMasterConfig.MasterSlaveMode = TIM_MASTERSLAVEMODE_DISABLE;
  if (HAL_TIMEx_MasterConfigSynchronization(&htim5, &sMasterConfig) != HAL_OK)
  {
    _Error_Handler(__FILE__, __LINE__);
  }

}

/* TIM6 init function */
static void MX_TIM6_Init(void)
{

  TIM_MasterConfigTypeDef sMasterConfig;

  htim6.Instance = TIM6;
  htim6.Init.Prescaler = 108;
  htim6.Init.CounterMode = TIM_COUNTERMODE_UP;
  htim6.Init.Period = 50-1;
  htim6.Init.AutoReloadPreload = TIM_AUTORELOAD_PRELOAD_DISABLE;
  if (HAL_TIM_Base_Init(&htim6) != HAL_OK)
  {
    _Error_Handler(__FILE__, __LINE__);
  }

  sMasterConfig.MasterOutputTrigger = TIM_TRGO_RESET;
  sMasterConfig.MasterSlaveMode = TIM_MASTERSLAVEMODE_DISABLE;
  if (HAL_TIMEx_MasterConfigSynchronization(&htim6, &sMasterConfig) != HAL_OK)
  {
    _Error_Handler(__FILE__, __LINE__);
  }

}

/* TIM9 init function */
static void MX_TIM9_Init(void)
{

  TIM_SlaveConfigTypeDef sSlaveConfig;

  htim9.Instance = TIM9;
  htim9.Init.Prescaler = 0;
  htim9.Init.CounterMode = TIM_COUNTERMODE_UP;
  htim9.Init.Period = 4-1;
  htim9.Init.ClockDivision = TIM_CLOCKDIVISION_DIV1;
  htim9.Init.AutoReloadPreload = TIM_AUTORELOAD_PRELOAD_DISABLE;
  if (HAL_TIM_Base_Init(&htim9) != HAL_OK)
  {
    _Error_Handler(__FILE__, __LINE__);
  }

  sSlaveConfig.SlaveMode = TIM_SLAVEMODE_EXTERNAL1;
  sSlaveConfig.InputTrigger = TIM_TS_TI2FP2;
  sSlaveConfig.TriggerPolarity = TIM_TRIGGERPOLARITY_RISING;
  sSlaveConfig.TriggerFilter = 0;
  if (HAL_TIM_SlaveConfigSynchronization(&htim9, &sSlaveConfig) != HAL_OK)
  {
    _Error_Handler(__FILE__, __LINE__);
  }

}

/* USART1 init function */
static void MX_USART1_UART_Init(void)
{

  huart1.Instance = USART1;
  huart1.Init.BaudRate = 115200;
  huart1.Init.WordLength = UART_WORDLENGTH_7B;
  huart1.Init.StopBits = UART_STOPBITS_1;
  huart1.Init.Parity = UART_PARITY_NONE;
  huart1.Init.Mode = UART_MODE_TX_RX;
  huart1.Init.HwFlowCtl = UART_HWCONTROL_NONE;
  huart1.Init.OverSampling = UART_OVERSAMPLING_16;
  huart1.Init.OneBitSampling = UART_ONE_BIT_SAMPLE_DISABLE;
  huart1.AdvancedInit.AdvFeatureInit = UART_ADVFEATURE_NO_INIT;
  if (HAL_UART_Init(&huart1) != HAL_OK)
  {
    _Error_Handler(__FILE__, __LINE__);
  }

}

static void MX_DMA_Init(void)
{
  /* DMA controller clock enable */
  __HAL_RCC_DMA1_CLK_ENABLE();
  __HAL_RCC_DMA2_CLK_ENABLE();

  /* DMA interrupt init */
  /* DMA1_Stream0_IRQn interrupt configuration */
  HAL_NVIC_SetPriority(DMA1_Stream0_IRQn, 5, 0);
  HAL_NVIC_EnableIRQ(DMA1_Stream0_IRQn);
  /* DMA2_Stream1_IRQn interrupt configuration */
  HAL_NVIC_SetPriority(DMA2_Stream1_IRQn, 5, 0);
  HAL_NVIC_EnableIRQ(DMA2_Stream1_IRQn);
  /* DMA2_Stream2_IRQn interrupt configuration */
  HAL_NVIC_SetPriority(DMA2_Stream2_IRQn, 5, 0);
  HAL_NVIC_EnableIRQ(DMA2_Stream2_IRQn);
  /* DMA2_Stream4_IRQn interrupt configuration */
  HAL_NVIC_SetPriority(DMA2_Stream4_IRQn, 5, 0);
  HAL_NVIC_EnableIRQ(DMA2_Stream4_IRQn);
  /* DMA2_Stream6_IRQn interrupt configuration */
  HAL_NVIC_SetPriority(DMA2_Stream6_IRQn, 5, 0);
  HAL_NVIC_EnableIRQ(DMA2_Stream6_IRQn);
  /* DMA2_Stream7_IRQn interrupt configuration */
  HAL_NVIC_SetPriority(DMA2_Stream7_IRQn, 5, 0);
  HAL_NVIC_EnableIRQ(DMA2_Stream7_IRQn);

}

/** Configure pins as
        * Analog
        * Input
        * Output
        * EVENT_OUT
        * EXTI
     PD8   ------> USART3_TX
     PD9   ------> USART3_RX
     PA8   ------> RCC_MCO_1
*/
static void MX_GPIO_Init(void)
{

  GPIO_InitTypeDef GPIO_InitStruct;

  /* GPIO Ports Clock Enable */
  __HAL_RCC_GPIOE_CLK_ENABLE();
  __HAL_RCC_GPIOC_CLK_ENABLE();
  __HAL_RCC_GPIOF_CLK_ENABLE();
  __HAL_RCC_GPIOH_CLK_ENABLE();
  __HAL_RCC_GPIOA_CLK_ENABLE();
  __HAL_RCC_GPIOB_CLK_ENABLE();
  __HAL_RCC_GPIOG_CLK_ENABLE();
  __HAL_RCC_GPIOD_CLK_ENABLE();

  /*Configure GPIO pin Output Level */
  HAL_GPIO_WritePin(STROB_GPIO_Port, STROB_Pin, GPIO_PIN_RESET);

  /*Configure GPIO pin Output Level */
  HAL_GPIO_WritePin(GPIOC, SYNC_ADC_Pin|GPIO0_ADC_Pin|BUSE_SIG_Pin, GPIO_PIN_RESET);

  /*Configure GPIO pin Output Level */
  HAL_GPIO_WritePin(ENABLE_OUT_1_GPIO_Port, ENABLE_OUT_1_Pin, GPIO_PIN_RESET);

  /*Configure GPIO pin Output Level */
  HAL_GPIO_WritePin(OE_GPIO_Port, OE_Pin, GPIO_PIN_RESET);

  /*Configure GPIO pin Output Level */
  HAL_GPIO_WritePin(GPIOD, EN_VCC_75_Pin|GPIO1_ADC_Pin|GPIO2_ADC_Pin|GPIO3_ADC_Pin
                          |GPIO4_ADC_Pin, GPIO_PIN_RESET);

  /*Configure GPIO pin Output Level */
  HAL_GPIO_WritePin(GPIOG, ENABLE_AIR_Pin|AIR_CS_Pin|EN_VCC_7_5_Pin|EN_VCC_150_Pin
                          |USB_PowerSwitchOn_Pin|EN_VCC_250_Pin|U_CS_Pin, GPIO_PIN_RESET);

  /*Configure GPIO pin Output Level */
  HAL_GPIO_WritePin(BUSE_SYNC_GPIO_Port, BUSE_SYNC_Pin, GPIO_PIN_SET);

  /*Configure GPIO pin Output Level */
  HAL_GPIO_WritePin(ENABLE_OUT_7_GPIO_Port, ENABLE_OUT_7_Pin, GPIO_PIN_SET);

  /*Configure GPIO pin : User_Blue_Button_Pin */
  GPIO_InitStruct.Pin = User_Blue_Button_Pin;
  GPIO_InitStruct.Mode = GPIO_MODE_INPUT;
  GPIO_InitStruct.Pull = GPIO_NOPULL;
  HAL_GPIO_Init(User_Blue_Button_GPIO_Port, &GPIO_InitStruct);

  /*Configure GPIO pins : ADR0_Pin ADR1_Pin ADR2_Pin */
  GPIO_InitStruct.Pin = ADR0_Pin|ADR1_Pin|ADR2_Pin;
  GPIO_InitStruct.Mode = GPIO_MODE_INPUT;
  GPIO_InitStruct.Pull = GPIO_PULLDOWN;
  HAL_GPIO_Init(GPIOF, &GPIO_InitStruct);

  /*Configure GPIO pin : STROB_Pin */
  GPIO_InitStruct.Pin = STROB_Pin;
  GPIO_InitStruct.Mode = GPIO_MODE_OUTPUT_PP;
  GPIO_InitStruct.Pull = GPIO_NOPULL;
  GPIO_InitStruct.Speed = GPIO_SPEED_FREQ_LOW;
  HAL_GPIO_Init(STROB_GPIO_Port, &GPIO_InitStruct);

  /*Configure GPIO pins : ADR3_Pin TEST_250_Pin FAULT_OUT_7_Pin FAULT_250A_Pin
                           FAULT_75A_Pin TEST_150_Pin */
  GPIO_InitStruct.Pin = ADR3_Pin|TEST_250_Pin|FAULT_OUT_7_Pin|FAULT_250A_Pin
                          |FAULT_75A_Pin|TEST_150_Pin;
  GPIO_InitStruct.Mode = GPIO_MODE_INPUT;
  GPIO_InitStruct.Pull = GPIO_NOPULL;
  HAL_GPIO_Init(GPIOF, &GPIO_InitStruct);

  /*Configure GPIO pins : SYNC_ADC_Pin GPIO0_ADC_Pin BUSE_SIG_Pin */
  GPIO_InitStruct.Pin = SYNC_ADC_Pin|GPIO0_ADC_Pin|BUSE_SIG_Pin;
  GPIO_InitStruct.Mode = GPIO_MODE_OUTPUT_PP;
  GPIO_InitStruct.Pull = GPIO_NOPULL;
  GPIO_InitStruct.Speed = GPIO_SPEED_FREQ_LOW;
  HAL_GPIO_Init(GPIOC, &GPIO_InitStruct);

  /*Configure GPIO pin : ENABLE_OUT_1_Pin */
  GPIO_InitStruct.Pin = ENABLE_OUT_1_Pin;
  GPIO_InitStruct.Mode = GPIO_MODE_OUTPUT_PP;
  GPIO_InitStruct.Pull = GPIO_NOPULL;
  GPIO_InitStruct.Speed = GPIO_SPEED_FREQ_LOW;
  HAL_GPIO_Init(ENABLE_OUT_1_GPIO_Port, &GPIO_InitStruct);

  /*Configure GPIO pin : FAULT_OUT_1_Pin */
  GPIO_InitStruct.Pin = FAULT_OUT_1_Pin;
  GPIO_InitStruct.Mode = GPIO_MODE_INPUT;
  GPIO_InitStruct.Pull = GPIO_NOPULL;
  HAL_GPIO_Init(FAULT_OUT_1_GPIO_Port, &GPIO_InitStruct);

  /*Configure GPIO pins : ADR6_Pin ADR7_Pin */
  GPIO_InitStruct.Pin = ADR6_Pin|ADR7_Pin;
  GPIO_InitStruct.Mode = GPIO_MODE_INPUT;
  GPIO_InitStruct.Pull = GPIO_PULLUP;
  HAL_GPIO_Init(GPIOG, &GPIO_InitStruct);

  /*Configure GPIO pin : OE_Pin */
  GPIO_InitStruct.Pin = OE_Pin;
  GPIO_InitStruct.Mode = GPIO_MODE_OUTPUT_PP;
  GPIO_InitStruct.Pull = GPIO_NOPULL;
  GPIO_InitStruct.Speed = GPIO_SPEED_FREQ_LOW;
  HAL_GPIO_Init(OE_GPIO_Port, &GPIO_InitStruct);

  /*Configure GPIO pins : TEST_75_Pin TEST_7_5_Pin */
  GPIO_InitStruct.Pin = TEST_75_Pin|TEST_7_5_Pin;
  GPIO_InitStruct.Mode = GPIO_MODE_INPUT;
  GPIO_InitStruct.Pull = GPIO_NOPULL;
  HAL_GPIO_Init(GPIOE, &GPIO_InitStruct);

  /*Configure GPIO pins : STLK_RX_Pin STLK_TX_Pin */
  GPIO_InitStruct.Pin = STLK_RX_Pin|STLK_TX_Pin;
  GPIO_InitStruct.Mode = GPIO_MODE_AF_PP;
  GPIO_InitStruct.Pull = GPIO_NOPULL;
  GPIO_InitStruct.Speed = GPIO_SPEED_FREQ_VERY_HIGH;
  GPIO_InitStruct.Alternate = GPIO_AF7_USART3;
  HAL_GPIO_Init(GPIOD, &GPIO_InitStruct);

  /*Configure GPIO pins : EN_VCC_75_Pin GPIO1_ADC_Pin GPIO2_ADC_Pin GPIO3_ADC_Pin
                           GPIO4_ADC_Pin */
  GPIO_InitStruct.Pin = EN_VCC_75_Pin|GPIO1_ADC_Pin|GPIO2_ADC_Pin|GPIO3_ADC_Pin
                          |GPIO4_ADC_Pin;
  GPIO_InitStruct.Mode = GPIO_MODE_OUTPUT_PP;
  GPIO_InitStruct.Pull = GPIO_NOPULL;
  GPIO_InitStruct.Speed = GPIO_SPEED_FREQ_LOW;
  HAL_GPIO_Init(GPIOD, &GPIO_InitStruct);

  /*Configure GPIO pins : FAULT_7_5A_Pin FAULT_150A_Pin */
  GPIO_InitStruct.Pin = FAULT_7_5A_Pin|FAULT_150A_Pin;
  GPIO_InitStruct.Mode = GPIO_MODE_INPUT;
  GPIO_InitStruct.Pull = GPIO_NOPULL;
  HAL_GPIO_Init(GPIOD, &GPIO_InitStruct);

  /*Configure GPIO pins : ENABLE_AIR_Pin AIR_CS_Pin EN_VCC_7_5_Pin EN_VCC_150_Pin
                           USB_PowerSwitchOn_Pin EN_VCC_250_Pin U_CS_Pin ENABLE_OUT_7_Pin */
  GPIO_InitStruct.Pin = ENABLE_AIR_Pin|AIR_CS_Pin|EN_VCC_7_5_Pin|EN_VCC_150_Pin
                          |USB_PowerSwitchOn_Pin|EN_VCC_250_Pin|U_CS_Pin|ENABLE_OUT_7_Pin;
  GPIO_InitStruct.Mode = GPIO_MODE_OUTPUT_PP;
  GPIO_InitStruct.Pull = GPIO_NOPULL;
  GPIO_InitStruct.Speed = GPIO_SPEED_FREQ_LOW;
  HAL_GPIO_Init(GPIOG, &GPIO_InitStruct);

  /*Configure GPIO pins : USB_OverCurrent_Pin DIN_ADC_Pin */
  GPIO_InitStruct.Pin = USB_OverCurrent_Pin|DIN_ADC_Pin;
  GPIO_InitStruct.Mode = GPIO_MODE_INPUT;
  GPIO_InitStruct.Pull = GPIO_NOPULL;
  HAL_GPIO_Init(GPIOG, &GPIO_InitStruct);

  /*Configure GPIO pin : PA8 */
  GPIO_InitStruct.Pin = GPIO_PIN_8;
  GPIO_InitStruct.Mode = GPIO_MODE_AF_PP;
  GPIO_InitStruct.Pull = GPIO_NOPULL;
  GPIO_InitStruct.Speed = GPIO_SPEED_FREQ_LOW;
  GPIO_InitStruct.Alternate = GPIO_AF0_MCO;
  HAL_GPIO_Init(GPIOA, &GPIO_InitStruct);

  /*Configure GPIO pin : BUSE_SYNC_Pin */
  GPIO_InitStruct.Pin = BUSE_SYNC_Pin;
  GPIO_InitStruct.Mode = GPIO_MODE_OUTPUT_PP;
  GPIO_InitStruct.Pull = GPIO_NOPULL;
  GPIO_InitStruct.Speed = GPIO_SPEED_FREQ_LOW;
  HAL_GPIO_Init(BUSE_SYNC_GPIO_Port, &GPIO_InitStruct);

  /*Configure GPIO pins : ADR5_Pin ADR4_Pin */
  GPIO_InitStruct.Pin = ADR5_Pin|ADR4_Pin;
  GPIO_InitStruct.Mode = GPIO_MODE_INPUT;
  GPIO_InitStruct.Pull = GPIO_PULLDOWN;
  HAL_GPIO_Init(GPIOD, &GPIO_InitStruct);

  /*Configure GPIO pin : SIG_SYNC_TIM_Pin */
  GPIO_InitStruct.Pin = SIG_SYNC_TIM_Pin;
  GPIO_InitStruct.Mode = GPIO_MODE_IT_RISING;
  GPIO_InitStruct.Pull = GPIO_NOPULL;
  HAL_GPIO_Init(SIG_SYNC_TIM_GPIO_Port, &GPIO_InitStruct);

  /* EXTI interrupt init*/
  HAL_NVIC_SetPriority(EXTI9_5_IRQn, 5, 0);
  HAL_NVIC_EnableIRQ(EXTI9_5_IRQn);

}

/* StartDefaultTask function */
void StartDefaultTask(void const * argument)
{
  /* init code for LWIP */
  MX_LWIP_Init();

  /* USER CODE BEGIN 5 */
	MB_TCP_Init();
	MBMaster_RTU_Init();
	UDP_Send_Init();
	vTaskDelete(NULL);

  /* USER CODE END 5 */
}

void _Error_Handler(char * file, int line)
{
  while(1)
  {
  }
}

/************************ (C) COPYRIGHT STMicroelectronics *****END OF FILE****/
